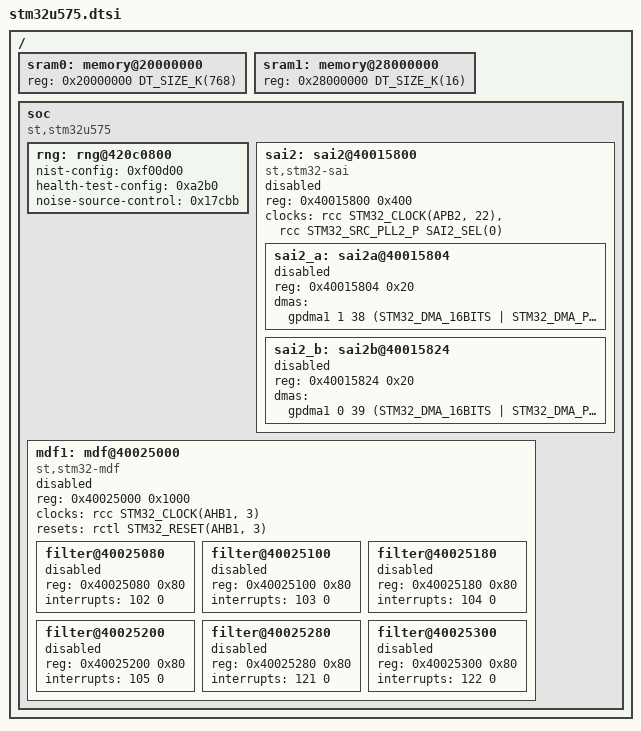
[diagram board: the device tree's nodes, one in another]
/*
 * Copyright (c) 2021 Linaro Limited
 * Copyright (c) 2025 Harris Tomy
 *
 * SPDX-License-Identifier: Apache-2.0
 */

#include <st/u5/stm32u5_usbotg_fs.dtsi>
#include <zephyr/dt-bindings/memory-controller/stm32-fmc-nor-psram.h>

/ {
	sram0: memory@20000000 {
		/* SRAM1 + SRAM2 + SRAM3 */
		reg = <0x20000000 DT_SIZE_K(768)>;
	};

	sram1: memory@28000000 {
		/* SRAM4, low-power background autonomous mode */
		reg = <0x28000000 DT_SIZE_K(16)>;
	};

	soc {
		compatible = "st,stm32u575", "st,stm32u5", "simple-bus";

		rng: rng@420c0800 {
			nist-config = <0xf00d00>;
			health-test-config = <0xa2b0>;
			noise-source-control = <0x17cbb>;
		};

		sai2: sai2@40015800 {
			compatible = "st,stm32-sai";
			#address-cells = <1>;
			#size-cells = <1>;
			reg = <0x40015800 0x400>;
			ranges;
			clocks = <&rcc STM32_CLOCK(APB2, 22)>,
				 <&rcc STM32_SRC_PLL2_P SAI2_SEL(0)>;
			clock-names = "sai_ck", "sai_ker_ck";
			status = "disabled";

			sai2_a: sai2a@40015804 {
				reg = <0x40015804 0x20>;
				dmas = <&gpdma1 1 38 (STM32_DMA_16BITS | STM32_DMA_PRIORITY_HIGH)>;
				#address-cells = <1>;
				#size-cells = <0>;
				status = "disabled";
			};

			sai2_b: sai2b@40015824 {
				reg = <0x40015824 0x20>;
				dmas = <&gpdma1 0 39 (STM32_DMA_16BITS | STM32_DMA_PRIORITY_HIGH)>;
				#address-cells = <1>;
				#size-cells = <0>;
				status = "disabled";
			};
		};

		mdf1: mdf@40025000 {
			compatible = "st,stm32-mdf";
			reg = <0x40025000 0x1000>;
			clocks = <&rcc STM32_CLOCK(AHB1, 3)>;
			clock-names = "pclk";
			resets = <&rctl STM32_RESET(AHB1, 3)>;
			#address-cells = <1>;
			#size-cells = <1>;
			ranges;
			status = "disabled";

			filter@40025080 {
				reg = <0x40025080 0x80>;
				interrupts = <102 0>;
				status = "disabled";
			};

			filter@40025100 {
				reg = <0x40025100 0x80>;
				interrupts = <103 0>;
				status = "disabled";
			};

			filter@40025180 {
				reg = <0x40025180 0x80>;
				interrupts = <104 0>;
				status = "disabled";
			};

			filter@40025200 {
				reg = <0x40025200 0x80>;
				interrupts = <105 0>;
				status = "disabled";
			};

			filter@40025280 {
				reg = <0x40025280 0x80>;
				interrupts = <121 0>;
				status = "disabled";
			};

			filter@40025300 {
				reg = <0x40025300 0x80>;
				interrupts = <122 0>;
				status = "disabled";
			};
		};
	};
};
